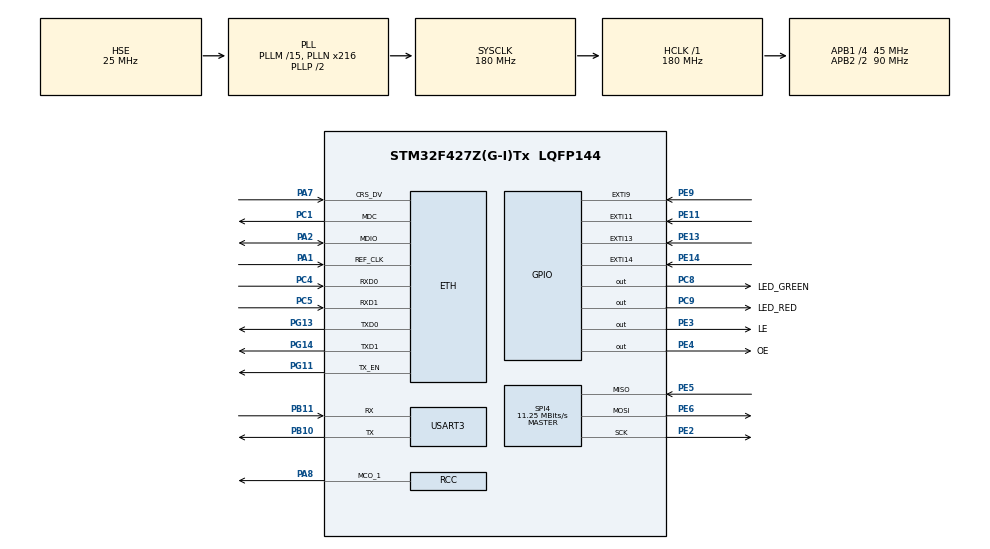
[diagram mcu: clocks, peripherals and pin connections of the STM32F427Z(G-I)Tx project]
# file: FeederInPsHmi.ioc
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ETH.MediaInterface=ETH_MEDIA_INTERFACE_RMII
ETH.PhyAddress=0
FREERTOS.Tasks01=defaultTask,24,128,StartDefaultTask,Default,NULL,Dynamic,NULL,NULL
LWIP.Version=v2.1.2_Cube
Mcu.Family=STM32F4
Mcu.Name=STM32F427Z(G-I)Tx
Mcu.Package=LQFP144
NVIC.EXTI15_10_IRQn=true\:0\:0\:false\:false\:true\:false\:true\:true
NVIC.EXTI9_5_IRQn=true\:0\:0\:false\:false\:true\:false\:true\:true
NVIC.PriorityGroup=NVIC_PRIORITYGROUP_4
NVIC.USART3_IRQn=true\:0\:0\:true\:false\:true\:false\:true\:true
PA1.Mode=RMII
PA1.Signal=ETH_REF_CLK
PA2.Mode=RMII
PA2.Signal=ETH_MDIO
PA7.Mode=RMII
PA7.Signal=ETH_CRS_DV
PA8.Mode=Clock-out-1
PA8.Signal=RCC_MCO_1
PB10.Mode=Asynchronous
PB10.Signal=USART3_TX
PB11.Mode=Asynchronous
PB11.Signal=USART3_RX
PC1.Mode=RMII
PC1.Signal=ETH_MDC
PC4.Mode=RMII
PC4.Signal=ETH_RXD0
PC5.Mode=RMII
PC5.Signal=ETH_RXD1
PC8.GPIO_Label=LED_GREEN
PC8.Signal=GPIO_Output
PC9.GPIO_Label=LED_RED
PC9.Signal=GPIO_Output
PE11.Signal=GPXTI11
PE13.Signal=GPXTI13
PE14.Signal=GPXTI14
PE2.Mode=Full_Duplex_Master
PE2.Signal=SPI4_SCK
PE3.GPIO_Label=LE
PE3.Signal=GPIO_Output
PE4.GPIO_Label=OE
PE4.Signal=GPIO_Output
PE5.Mode=Full_Duplex_Master
PE5.Signal=SPI4_MISO
PE6.Mode=Full_Duplex_Master
PE6.Signal=SPI4_MOSI
PE9.Signal=GPXTI9
PG11.Mode=RMII
PG11.Signal=ETH_TX_EN
PG13.Mode=RMII
PG13.Signal=ETH_TXD0
PG14.Mode=RMII
PG14.Signal=ETH_TXD1
PH0/OSC_IN.Mode=HSE-External-Clock-Source
PH0/OSC_IN.Signal=RCC_OSC_IN
PH1/OSC_OUT.Mode=HSE-External-Clock-Source
PH1/OSC_OUT.Signal=RCC_OSC_OUT
ProjectManager.HeapSize=0x200
ProjectManager.StackSize=0x400
ProjectManager.TargetToolchain=STM32CubeIDE
RCC.48MHZClocksFreq_Value=90000000
RCC.AHBFreq_Value=180000000
RCC.APB1CLKDivider=RCC_HCLK_DIV4
RCC.APB1Freq_Value=45000000
RCC.APB1TimFreq_Value=90000000
RCC.APB2CLKDivider=RCC_HCLK_DIV2
RCC.APB2Freq_Value=90000000
RCC.APB2TimFreq_Value=180000000
RCC.CortexFreq_Value=180000000
RCC.HCLKFreq_Value=180000000
RCC.HSE_VALUE=25000000
RCC.HSI_VALUE=16000000
RCC.LSE_VALUE=32768
RCC.PLLM=15
RCC.PLLN=216
RCC.PLLSourceVirtual=RCC_PLLSOURCE_HSE
RCC.RCC_MCO1Source=RCC_MCO1SOURCE_HSE
RCC.SYSCLKFreq_VALUE=180000000
RCC.SYSCLKSource=RCC_SYSCLKSOURCE_PLLCLK
RCC.VCOOutputFreq_Value=360000000
SPI4.BaudRatePrescaler=SPI_BAUDRATEPRESCALER_8
SPI4.CalculateBaudRate=11.25 MBits/s
SPI4.Direction=SPI_DIRECTION_2LINES
SPI4.Mode=SPI_MODE_MASTER
SPI4.VirtualType=VM_MASTER
USART3.VirtualMode=VM_ASYNC
VP_FREERTOS_VS_CMSIS_V2.Mode=CMSIS_V2
VP_LWIP_VS_Enabled.Mode=Enabled
board=custom

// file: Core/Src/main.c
/* USER CODE BEGIN Header */
/**
  ******************************************************************************
  * @file           : main.c
  * @brief          : Main program body
  ******************************************************************************
  * @attention
  *
  * <h2><center>&copy; Copyright (c) 2020 STMicroelectronics.
  * All rights reserved.</center></h2>
  *
  * This software component is licensed by ST under BSD 3-Clause license,
  * the "License"; You may not use this file except in compliance with the
  * License. You may obtain a copy of the License at:
  *                        opensource.org/licenses/BSD-3-Clause
  *
  ******************************************************************************
  */
/* USER CODE END Header */

#include "main.h"
#include "cmsis_os.h"
#include "lwip.h"

/* USER CODE BEGIN Includes */
#include "application.h"
//#include "lwip/api.h"
//#include "lwip/sys.h"
//#include "netconf.h"
/* USER CODE END Includes */

SPI_HandleTypeDef hspi4;

UART_HandleTypeDef huart3;

/* Definitions for defaultTask */
osThreadId_t defaultTaskHandle;
const osThreadAttr_t defaultTask_attributes = {
  .name = "defaultTask",
  .priority = (osPriority_t) osPriorityNormal,
  .stack_size = 128 * 4
};

void SystemClock_Config(void);
static void MX_GPIO_Init(void);
static void MX_SPI4_Init(void);
static void MX_USART3_UART_Init(void);
void StartDefaultTask(void *argument);

int main(void)
{

  /* MCU Configuration--------------------------------------------------------*/

  /* Reset of all peripherals, Initializes the Flash interface and the Systick. */
  HAL_Init();

  /* Configure the system clock */
  SystemClock_Config();

  /* Initialize all configured peripherals */
  MX_GPIO_Init();
  MX_SPI4_Init();
  MX_USART3_UART_Init();

  /* Init scheduler */
  osKernelInitialize();

  /* Create the thread(s) */
  /* creation of defaultTask */
  defaultTaskHandle = osThreadNew(StartDefaultTask, NULL, &defaultTask_attributes);

  /* USER CODE BEGIN RTOS_THREADS */
  /* add threads, ... */
  application();
  /* USER CODE END RTOS_THREADS */

  /* Start scheduler */
  osKernelStart();

  /* We should never get here as control is now taken by the scheduler */
  /* Infinite loop */
  while (1)
  {

  }
}

void SystemClock_Config(void)
{
  RCC_OscInitTypeDef RCC_OscInitStruct = {0};
  RCC_ClkInitTypeDef RCC_ClkInitStruct = {0};

  /** Configure the main internal regulator output voltage
  */
  __HAL_RCC_PWR_CLK_ENABLE();
  __HAL_PWR_VOLTAGESCALING_CONFIG(PWR_REGULATOR_VOLTAGE_SCALE1);
  /** Initializes the CPU, AHB and APB busses clocks
  */
  RCC_OscInitStruct.OscillatorType = RCC_OSCILLATORTYPE_HSE;
  RCC_OscInitStruct.HSEState = RCC_HSE_BYPASS;
  RCC_OscInitStruct.PLL.PLLState = RCC_PLL_ON;
  RCC_OscInitStruct.PLL.PLLSource = RCC_PLLSOURCE_HSE;
  RCC_OscInitStruct.PLL.PLLM = 15;
  RCC_OscInitStruct.PLL.PLLN = 216;
  RCC_OscInitStruct.PLL.PLLP = RCC_PLLP_DIV2;
  RCC_OscInitStruct.PLL.PLLQ = 4;
  if (HAL_RCC_OscConfig(&RCC_OscInitStruct) != HAL_OK)
  {
    Error_Handler();
  }
  /** Activate the Over-Drive mode
  */
  if (HAL_PWREx_EnableOverDrive() != HAL_OK)
  {
    Error_Handler();
  }
  /** Initializes the CPU, AHB and APB busses clocks
  */
  RCC_ClkInitStruct.ClockType = RCC_CLOCKTYPE_HCLK|RCC_CLOCKTYPE_SYSCLK
                              |RCC_CLOCKTYPE_PCLK1|RCC_CLOCKTYPE_PCLK2;
  RCC_ClkInitStruct.SYSCLKSource = RCC_SYSCLKSOURCE_PLLCLK;
  RCC_ClkInitStruct.AHBCLKDivider = RCC_SYSCLK_DIV1;
  RCC_ClkInitStruct.APB1CLKDivider = RCC_HCLK_DIV4;
  RCC_ClkInitStruct.APB2CLKDivider = RCC_HCLK_DIV2;

  if (HAL_RCC_ClockConfig(&RCC_ClkInitStruct, FLASH_LATENCY_5) != HAL_OK)
  {
    Error_Handler();
  }
  HAL_RCC_MCOConfig(RCC_MCO1, RCC_MCO1SOURCE_HSE, RCC_MCODIV_1);
}

static void MX_SPI4_Init(void)
{

  /* SPI4 parameter configuration*/
  hspi4.Instance = SPI4;
  hspi4.Init.Mode = SPI_MODE_MASTER;
  hspi4.Init.Direction = SPI_DIRECTION_2LINES;
  hspi4.Init.DataSize = SPI_DATASIZE_8BIT;
  hspi4.Init.CLKPolarity = SPI_POLARITY_LOW;
  hspi4.Init.CLKPhase = SPI_PHASE_1EDGE;
  hspi4.Init.NSS = SPI_NSS_SOFT;
  hspi4.Init.BaudRatePrescaler = SPI_BAUDRATEPRESCALER_8;
  hspi4.Init.FirstBit = SPI_FIRSTBIT_MSB;
  hspi4.Init.TIMode = SPI_TIMODE_DISABLE;
  hspi4.Init.CRCCalculation = SPI_CRCCALCULATION_DISABLE;
  hspi4.Init.CRCPolynomial = 10;
  if (HAL_SPI_Init(&hspi4) != HAL_OK)
  {
    Error_Handler();
  }

}

static void MX_USART3_UART_Init(void)
{

  huart3.Instance = USART3;
  huart3.Init.BaudRate = 115200;
  huart3.Init.WordLength = UART_WORDLENGTH_8B;
  huart3.Init.StopBits = UART_STOPBITS_1;
  huart3.Init.Parity = UART_PARITY_NONE;
  huart3.Init.Mode = UART_MODE_TX_RX;
  huart3.Init.HwFlowCtl = UART_HWCONTROL_NONE;
  huart3.Init.OverSampling = UART_OVERSAMPLING_16;
  if (HAL_UART_Init(&huart3) != HAL_OK)
  {
    Error_Handler();
  }

}

static void MX_GPIO_Init(void)
{
  GPIO_InitTypeDef GPIO_InitStruct = {0};

  /* GPIO Ports Clock Enable */
  __HAL_RCC_GPIOE_CLK_ENABLE();
  __HAL_RCC_GPIOH_CLK_ENABLE();
  __HAL_RCC_GPIOC_CLK_ENABLE();
  __HAL_RCC_GPIOA_CLK_ENABLE();
  __HAL_RCC_GPIOB_CLK_ENABLE();
  __HAL_RCC_GPIOG_CLK_ENABLE();

  /*Configure GPIO pin Output Level */
  HAL_GPIO_WritePin(GPIOE, LE_Pin|OE_Pin, GPIO_PIN_RESET);

  /*Configure GPIO pin Output Level */
  HAL_GPIO_WritePin(GPIOC, LED_GREEN_Pin|LED_RED_Pin, GPIO_PIN_RESET);

  /*Configure GPIO pins : LE_Pin OE_Pin */
  GPIO_InitStruct.Pin = LE_Pin|OE_Pin;
  GPIO_InitStruct.Mode = GPIO_MODE_OUTPUT_PP;
  GPIO_InitStruct.Pull = GPIO_NOPULL;
  GPIO_InitStruct.Speed = GPIO_SPEED_FREQ_LOW;
  HAL_GPIO_Init(GPIOE, &GPIO_InitStruct);

  /*Configure GPIO pins : PE9 PE11 PE13 PE14 */
  GPIO_InitStruct.Pin = GPIO_PIN_9|GPIO_PIN_11|GPIO_PIN_13|GPIO_PIN_14;
  GPIO_InitStruct.Mode = GPIO_MODE_IT_RISING;
  GPIO_InitStruct.Pull = GPIO_NOPULL;
  HAL_GPIO_Init(GPIOE, &GPIO_InitStruct);

  /*Configure GPIO pins : LED_GREEN_Pin LED_RED_Pin */
  GPIO_InitStruct.Pin = LED_GREEN_Pin|LED_RED_Pin;
  GPIO_InitStruct.Mode = GPIO_MODE_OUTPUT_PP;
  GPIO_InitStruct.Pull = GPIO_NOPULL;
  GPIO_InitStruct.Speed = GPIO_SPEED_FREQ_LOW;
  HAL_GPIO_Init(GPIOC, &GPIO_InitStruct);

  /*Configure GPIO pin : PA8 */
  GPIO_InitStruct.Pin = GPIO_PIN_8;
  GPIO_InitStruct.Mode = GPIO_MODE_AF_PP;
  GPIO_InitStruct.Pull = GPIO_NOPULL;
  GPIO_InitStruct.Speed = GPIO_SPEED_FREQ_LOW;
  GPIO_InitStruct.Alternate = GPIO_AF0_MCO;
  HAL_GPIO_Init(GPIOA, &GPIO_InitStruct);

  /* EXTI interrupt init*/
  HAL_NVIC_SetPriority(EXTI9_5_IRQn, 0, 0);
  HAL_NVIC_EnableIRQ(EXTI9_5_IRQn);

  HAL_NVIC_SetPriority(EXTI15_10_IRQn, 0, 0);
  HAL_NVIC_EnableIRQ(EXTI15_10_IRQn);

}

void StartDefaultTask(void *argument)
{
  /* init code for LWIP */
  MX_LWIP_Init();
  /* USER CODE BEGIN 5 */

 /* conn = netconn_new(NETCONN_UDP);
  if (conn!= NULL) {
    err = netconn_bind(conn, IP_ADDR_ANY, 7);
*/
  /* Infinite loop */
  for(;;)
  {
	  /*  if (err == ERR_OK)
	  {
		    pcb = udp_new();
		    udp_bind(pcb, &dstaddr, src_port);
		    //udp_recv(pcb, RecvUTPCallBack, NULL);
		    udp_connect(pcb, &dstaddr, dst_port);

		    pb = pbuf_alloc(PBUF_TRANSPORT, sizeof((str)), PBUF_REF);
		    pb->payload = str;
		    pb->len = pb->tot_len = sizeof((str));

		    udp_sendto(pcb, pb, &dstaddr, dst_port);
		    udp_disconnect(pcb);
		    udp_remove(pcb);
		    pbuf_free(pb);
		    vTaskDelay(1000);
	   }*/

    osDelay(1);
  }
  /* USER CODE END 5 */
}

void Error_Handler(void)
{
}

/************************ (C) COPYRIGHT STMicroelectronics *****END OF FILE****/
